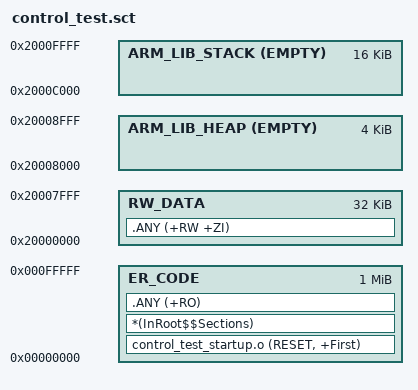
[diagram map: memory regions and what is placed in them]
LR_CODE 0x00000000 0x00100000 {
    ER_CODE 0x00000000 0x00100000 {
        control_test_startup.o (RESET, +First)
        *(InRoot$$Sections)
        .ANY (+RO)
    }
    RW_DATA 0x20000000 0x00008000 {
        .ANY (+RW +ZI)
    }
    ARM_LIB_HEAP 0x20008000 EMPTY 0x00001000 {}
    ARM_LIB_STACK 0x20010000 EMPTY -0x00004000 {}
}
